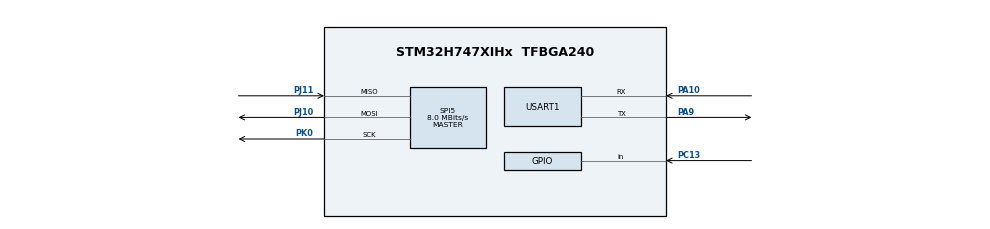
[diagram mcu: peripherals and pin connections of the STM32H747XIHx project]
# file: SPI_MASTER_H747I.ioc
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CortexM4.IPs=BDMA,DMA,FATFS_M4\:I,FREERTOS_M4\:I,IWDG2\:I,MDMA,NVIC2\:I,RCC,USB_DEVICE_M4\:I,USB_HOST_M4\:I,WWDG2\:I,ADC1\:I,DCMI\:I,TIM3\:I,DEBUG,PDM2PCM_M4\:I,PWR,RESMGR_UTILITY,SYS_M4\:I,CORTEX_M4\:I,OPENAMP_M4\:I,VREFBUF,GPIO
CortexM7.IPs=BDMA\:I,DMA\:I,FATFS_M7\:I,FREERTOS_M7\:I,IWDG1\:I,MDMA\:I,NVIC1\:I,RCC\:I,USB_DEVICE_M7\:I,USB_HOST_M7\:I,WWDG1\:I,CORTEX_M7\:I,DEBUG\:I,PDM2PCM_M7\:I,PWR\:I,RESMGR_UTILITY\:I,SYS\:I,OPENAMP_M7\:I,VREFBUF\:I,GPIO\:I,SPI5\:I,USART1\:I
CortexM7.Pins=PC13
Mcu.Family=STM32H7
Mcu.Name=STM32H747XIHx
Mcu.Package=TFBGA240
NVIC1.PriorityGroup=NVIC_PRIORITYGROUP_4
NVIC1.SPI5_IRQn=true\:0\:0\:false\:false\:true\:true\:true\:true
NVIC2.PriorityGroup=NVIC_PRIORITYGROUP_4
PA10.Mode=Asynchronous
PA10.PinAttribute=CortexM7
PA10.Signal=USART1_RX
PA9.Mode=Asynchronous
PA9.PinAttribute=CortexM7
PA9.Signal=USART1_TX
PC13.GPIO_PuPd=GPIO_PULLUP
PC13.PinAttribute=CortexM7
PC13.Signal=GPIO_Input
PJ10.Mode=Full_Duplex_Master
PJ10.PinAttribute=CortexM7
PJ10.Signal=SPI5_MOSI
PJ11.Mode=Full_Duplex_Master
PJ11.PinAttribute=CortexM7
PJ11.Signal=SPI5_MISO
PK0.Mode=Full_Duplex_Master
PK0.PinAttribute=CortexM7
PK0.Signal=SPI5_SCK
ProjectManager.HeapSize=M4-0x200,M7-0x200
ProjectManager.StackSize=M4-0x400,M7-0x400
ProjectManager.TargetToolchain=STM32CubeIDE
RCC.ADCFreq_Value=75000000
RCC.APB1Freq_Value=16000000
RCC.APB2Freq_Value=16000000
RCC.APB3Freq_Value=16000000
RCC.APB4Freq_Value=16000000
RCC.CortexFreq_Value=64000000
RCC.DIVM2=4
RCC.DIVN2=9
RCC.HCLKFreq_Value=16000000
RCC.HPRE=RCC_HCLK_DIV4
RCC.PLL2FRACN=3072
RCC.PWR_Regulator_Voltage_Scale=PWR_REGULATOR_VOLTAGE_SCALE1
RCC.SYSCLKFreq_VALUE=64000000
RCC.SupplySource=PWR_DIRECT_SMPS_SUPPLY
RCC.USBFreq_Value=129000000
SPI5.CalculateBaudRate=8.0 MBits/s
SPI5.DataSize=SPI_DATASIZE_8BIT
SPI5.Direction=SPI_DIRECTION_2LINES
SPI5.Mode=SPI_MODE_MASTER
SPI5.VirtualType=VM_MASTER
USART1.VirtualMode-Asynchronous=VM_ASYNC
VP_SYS_M4_VS_Systick.Mode=SysTick
board=STM32H747I-DISCO

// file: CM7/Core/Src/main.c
/* USER CODE BEGIN Header */
/**
  ******************************************************************************
  * @file           : main.c
  * @brief          : Main program body
  ******************************************************************************
  * @attention
  *
  * Copyright (c) 2024 STMicroelectronics.
  * All rights reserved.
  *
  * This software is licensed under terms that can be found in the LICENSE file
  * in the root directory of this software component.
  * If no LICENSE file comes with this software, it is provided AS-IS.
  *
  ******************************************************************************
  */
/* USER CODE END Header */
#include "main.h"

/* USER CODE BEGIN PD */

#ifndef HSEM_ID_0
#define HSEM_ID_0 (0U) /* HW semaphore 0*/
#endif

/* USER CODE END PD */

SPI_HandleTypeDef hspi5;

UART_HandleTypeDef huart1;

void SystemClock_Config(void);
static void MX_GPIO_Init(void);
static void MX_SPI5_Init(void);
static void MX_USART1_UART_Init(void);

int main(void)
{

/* USER CODE BEGIN Boot_Mode_Sequence_0 */
  int32_t timeout;
/* USER CODE END Boot_Mode_Sequence_0 */

/* USER CODE BEGIN Boot_Mode_Sequence_1 */
  /* Wait until CPU2 boots and enters in stop mode or timeout*/
  timeout = 0xFFFF;
  while((__HAL_RCC_GET_FLAG(RCC_FLAG_D2CKRDY) != RESET) && (timeout-- > 0));
  if ( timeout < 0 )
  {
  Error_Handler();
  }
/* USER CODE END Boot_Mode_Sequence_1 */
  /* MCU Configuration--------------------------------------------------------*/

  /* Reset of all peripherals, Initializes the Flash interface and the Systick. */
  HAL_Init();

  /* Configure the system clock */
  SystemClock_Config();
/* USER CODE BEGIN Boot_Mode_Sequence_2 */
/* When system initialization is finished, Cortex-M7 will release Cortex-M4 by means of
HSEM notification */
/*HW semaphore Clock enable*/
__HAL_RCC_HSEM_CLK_ENABLE();
/*Take HSEM */
HAL_HSEM_FastTake(HSEM_ID_0);
/*Release HSEM in order to notify the CPU2(CM4)*/
HAL_HSEM_Release(HSEM_ID_0,0);
/* wait until CPU2 wakes up from stop mode */
timeout = 0xFFFF;
while((__HAL_RCC_GET_FLAG(RCC_FLAG_D2CKRDY) == RESET) && (timeout-- > 0));
if ( timeout < 0 )
{
Error_Handler();
}
/* USER CODE END Boot_Mode_Sequence_2 */

  /* Initialize all configured peripherals */
  MX_GPIO_Init();
  MX_SPI5_Init();
  MX_USART1_UART_Init();
  /* USER CODE BEGIN 2 */
  uint8_t data_to_send = 0x01;

  /* USER CODE END 2 */

  /* Infinite loop */
  /* USER CODE BEGIN WHILE */
  while (1)
  {
	  if (HAL_GPIO_ReadPin(GPIOC, GPIO_PIN_13) == GPIO_PIN_SET) { // Button pressed

	              if(HAL_SPI_Transmit(&hspi5, &data_to_send, 1, HAL_MAX_DELAY)== HAL_OK)// Transmit SPI data
	              {
	              HAL_UART_Transmit(&huart1, (uint8_t *)"Tx_Success\r\n", 10, HAL_MAX_DELAY);
	              }
	              HAL_Delay(500); // Debounce delay
	          }
    /* USER CODE END WHILE */

  }
}

void SystemClock_Config(void)
{
  RCC_OscInitTypeDef RCC_OscInitStruct = {0};
  RCC_ClkInitTypeDef RCC_ClkInitStruct = {0};

  /** Supply configuration update enable
  */
  HAL_PWREx_ConfigSupply(PWR_DIRECT_SMPS_SUPPLY);

  /** Configure the main internal regulator output voltage
  */
  __HAL_PWR_VOLTAGESCALING_CONFIG(PWR_REGULATOR_VOLTAGE_SCALE1);

  while(!__HAL_PWR_GET_FLAG(PWR_FLAG_VOSRDY)) {}

  /** Initializes the RCC Oscillators according to the specified parameters
  * in the RCC_OscInitTypeDef structure.
  */
  RCC_OscInitStruct.OscillatorType = RCC_OSCILLATORTYPE_HSI;
  RCC_OscInitStruct.HSIState = RCC_HSI_DIV1;
  RCC_OscInitStruct.HSICalibrationValue = RCC_HSICALIBRATION_DEFAULT;
  RCC_OscInitStruct.PLL.PLLState = RCC_PLL_NONE;
  if (HAL_RCC_OscConfig(&RCC_OscInitStruct) != HAL_OK)
  {
    Error_Handler();
  }

  /** Initializes the CPU, AHB and APB buses clocks
  */
  RCC_ClkInitStruct.ClockType = RCC_CLOCKTYPE_HCLK|RCC_CLOCKTYPE_SYSCLK
                              |RCC_CLOCKTYPE_PCLK1|RCC_CLOCKTYPE_PCLK2
                              |RCC_CLOCKTYPE_D3PCLK1|RCC_CLOCKTYPE_D1PCLK1;
  RCC_ClkInitStruct.SYSCLKSource = RCC_SYSCLKSOURCE_HSI;
  RCC_ClkInitStruct.SYSCLKDivider = RCC_SYSCLK_DIV1;
  RCC_ClkInitStruct.AHBCLKDivider = RCC_HCLK_DIV4;
  RCC_ClkInitStruct.APB3CLKDivider = RCC_APB3_DIV1;
  RCC_ClkInitStruct.APB1CLKDivider = RCC_APB1_DIV1;
  RCC_ClkInitStruct.APB2CLKDivider = RCC_APB2_DIV1;
  RCC_ClkInitStruct.APB4CLKDivider = RCC_APB4_DIV1;

  if (HAL_RCC_ClockConfig(&RCC_ClkInitStruct, FLASH_LATENCY_0) != HAL_OK)
  {
    Error_Handler();
  }
}

static void MX_SPI5_Init(void)
{

  /* SPI5 parameter configuration*/
  hspi5.Instance = SPI5;
  hspi5.Init.Mode = SPI_MODE_MASTER;
  hspi5.Init.Direction = SPI_DIRECTION_2LINES;
  hspi5.Init.DataSize = SPI_DATASIZE_8BIT;
  hspi5.Init.CLKPolarity = SPI_POLARITY_LOW;
  hspi5.Init.CLKPhase = SPI_PHASE_1EDGE;
  hspi5.Init.NSS = SPI_NSS_SOFT;
  hspi5.Init.BaudRatePrescaler = SPI_BAUDRATEPRESCALER_2;
  hspi5.Init.FirstBit = SPI_FIRSTBIT_MSB;
  hspi5.Init.TIMode = SPI_TIMODE_DISABLE;
  hspi5.Init.CRCCalculation = SPI_CRCCALCULATION_DISABLE;
  hspi5.Init.CRCPolynomial = 0x0;
  hspi5.Init.NSSPMode = SPI_NSS_PULSE_ENABLE;
  hspi5.Init.NSSPolarity = SPI_NSS_POLARITY_LOW;
  hspi5.Init.FifoThreshold = SPI_FIFO_THRESHOLD_01DATA;
  hspi5.Init.TxCRCInitializationPattern = SPI_CRC_INITIALIZATION_ALL_ZERO_PATTERN;
  hspi5.Init.RxCRCInitializationPattern = SPI_CRC_INITIALIZATION_ALL_ZERO_PATTERN;
  hspi5.Init.MasterSSIdleness = SPI_MASTER_SS_IDLENESS_00CYCLE;
  hspi5.Init.MasterInterDataIdleness = SPI_MASTER_INTERDATA_IDLENESS_00CYCLE;
  hspi5.Init.MasterReceiverAutoSusp = SPI_MASTER_RX_AUTOSUSP_DISABLE;
  hspi5.Init.MasterKeepIOState = SPI_MASTER_KEEP_IO_STATE_DISABLE;
  hspi5.Init.IOSwap = SPI_IO_SWAP_DISABLE;
  if (HAL_SPI_Init(&hspi5) != HAL_OK)
  {
    Error_Handler();
  }

}

static void MX_USART1_UART_Init(void)
{

  huart1.Instance = USART1;
  huart1.Init.BaudRate = 115200;
  huart1.Init.WordLength = UART_WORDLENGTH_8B;
  huart1.Init.StopBits = UART_STOPBITS_1;
  huart1.Init.Parity = UART_PARITY_NONE;
  huart1.Init.Mode = UART_MODE_TX_RX;
  huart1.Init.HwFlowCtl = UART_HWCONTROL_NONE;
  huart1.Init.OverSampling = UART_OVERSAMPLING_16;
  huart1.Init.OneBitSampling = UART_ONE_BIT_SAMPLE_DISABLE;
  huart1.Init.ClockPrescaler = UART_PRESCALER_DIV1;
  huart1.AdvancedInit.AdvFeatureInit = UART_ADVFEATURE_NO_INIT;
  if (HAL_UART_Init(&huart1) != HAL_OK)
  {
    Error_Handler();
  }
  if (HAL_UARTEx_SetTxFifoThreshold(&huart1, UART_TXFIFO_THRESHOLD_1_8) != HAL_OK)
  {
    Error_Handler();
  }
  if (HAL_UARTEx_SetRxFifoThreshold(&huart1, UART_RXFIFO_THRESHOLD_1_8) != HAL_OK)
  {
    Error_Handler();
  }
  if (HAL_UARTEx_DisableFifoMode(&huart1) != HAL_OK)
  {
    Error_Handler();
  }

}

static void MX_GPIO_Init(void)
{
  GPIO_InitTypeDef GPIO_InitStruct = {0};

  /* GPIO Ports Clock Enable */
  __HAL_RCC_GPIOA_CLK_ENABLE();
  __HAL_RCC_GPIOC_CLK_ENABLE();
  __HAL_RCC_GPIOK_CLK_ENABLE();
  __HAL_RCC_GPIOJ_CLK_ENABLE();

  /*Configure GPIO pin : PC13 */
  GPIO_InitStruct.Pin = GPIO_PIN_13;
  GPIO_InitStruct.Mode = GPIO_MODE_INPUT;
  GPIO_InitStruct.Pull = GPIO_NOPULL;
  HAL_GPIO_Init(GPIOC, &GPIO_InitStruct);

}

void Error_Handler(void)
{
  __disable_irq();
  while (1)
  {
  }
}
